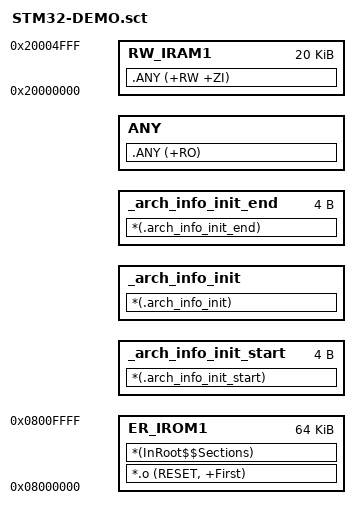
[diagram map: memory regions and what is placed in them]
; *************************************************************
; *** Scatter-Loading Description File generated by uVision ***
; *************************************************************

LR_IROM1 0x08000000 0x10000  {    ; load region size_region
  ER_IROM1 0x08000000 0x10000  {  ; load address = execution address
   *.o (RESET, +First)
   *(InRoot$$Sections)
  }

  _arch_info_init_start +0 0x00000004 {
    *(.arch_info_init_start)
  }

  _arch_info_init +0 {
    *(.arch_info_init)
  }

  _arch_info_init_end +0 0x00000004 {
    *(.arch_info_init_end)
  }

  ANY +0
  {
    .ANY (+RO)
  }

  RW_IRAM1 0x20000000 0x00005000  {  ; RW & ZI
   .ANY (+RW +ZI)
  }
}

